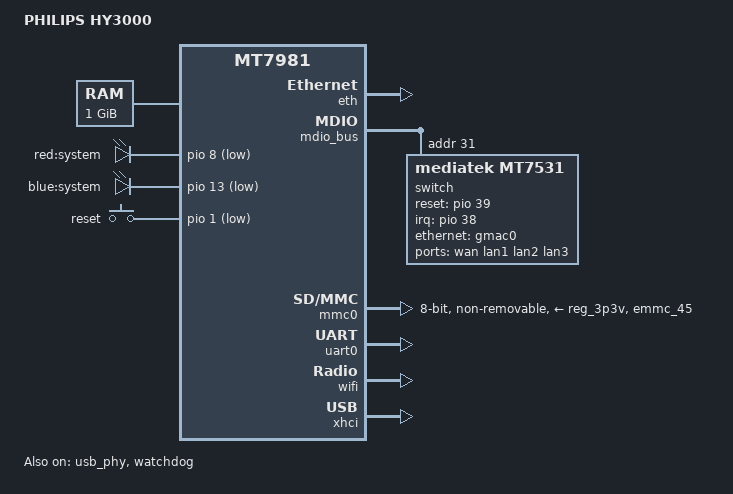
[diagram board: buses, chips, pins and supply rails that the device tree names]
// SPDX-License-Identifier: GPL-2.0-or-later OR MIT
/*
 * Copyright (C) 2023 Tianling Shen <cnsztl@immortalwrt.org>
 */

/dts-v1/;
#include <dt-bindings/gpio/gpio.h>
#include <dt-bindings/input/input.h>

#include "mt7981.dtsi"

/ {
	model = "PHILIPS HY3000";
	compatible = "philips,hy3000", "mediatek,mt7981";

	chosen {
		bootargs = "console=ttyS0,115200n1 loglevel=8 \
			    earlycon=uart8250,mmio32,0x11002000 \
			    root=PARTLABEL=rootfs rootwait rootfstype=squashfs,f2fs";
	};

	aliases {
		led-boot = &status_red_led;
		led-failsafe = &status_red_led;
		led-running = &status_blue_led;
		led-upgrade = &status_blue_led;
	};

	memory {
		reg = <0 0x40000000 0 0x40000000>;
	};

        leds {
                compatible = "gpio-leds";

		status_red_led: led@0 {
			label = "red:system";
			gpios = <&pio 8 GPIO_ACTIVE_LOW>;
		};

		status_blue_led: led@1 {
			label = "blue:system";
			gpios = <&pio 13 GPIO_ACTIVE_LOW>;
		};
	};

	gpio-keys {
		compatible = "gpio-keys";
		reset {
			label = "reset";
			linux,code = <KEY_RESTART>;
			gpios = <&pio 1 GPIO_ACTIVE_LOW>;
		};
	};
};

&eth {
	status = "okay";

	gmac0: mac@0 {
		compatible = "mediatek,eth-mac";
		reg = <0>;
		phy-mode = "2500base-x";

		fixed-link {
			speed = <2500>;
			full-duplex;
			pause;
		};
	};
	
	gmac1: mac@1 {
		compatible = "mediatek,eth-mac";
		reg = <1>;
		phy-mode = "2500base-x";

		fixed-link {
			speed = <2500>;
			full-duplex;
			pause;
		};
	};
};

&mdio_bus {
	switch: switch@1f {
		compatible = "mediatek,mt7531";
		reg = <31>;
		reset-gpios = <&pio 39 GPIO_ACTIVE_HIGH>;
		interrupt-controller;
		#interrupt-cells = <1>;
		interrupt-parent = <&pio>;
		interrupts = <38 IRQ_TYPE_LEVEL_HIGH>;
	};
};

&switch {
	ports {
		#address-cells = <1>;
		#size-cells = <0>;

		port@0 {
			reg = <0>;
			label = "wan";
		};

		port@1 {
			reg = <1>;
			label = "lan1";
		};

		port@2 {
			reg = <2>;
			label = "lan2";
		};
		
		port@3 {
			reg = <3>;
			label = "lan3";
		};

		port@6 {
			reg = <6>;
			ethernet = <&gmac0>;
			phy-mode = "2500base-x";

			fixed-link {
				speed = <2500>;
				full-duplex;
				pause;
			};
		};
	};
};

&mmc0 {
	bus-width = <8>;
	cap-mmc-highspeed;
	max-frequency = <52000000>;
	no-sd;
	no-sdio;
	non-removable;
	pinctrl-names = "default", "state_uhs";
	pinctrl-0 = <&mmc0_pins_default>;
	pinctrl-1 = <&mmc0_pins_uhs>;
	vmmc-supply = <&reg_3p3v>;
	non-removable;
	status = "okay";
};

&pio {
	mmc0_pins_default: mmc0-pins-default {
		mux {
			function = "flash";
			groups = "emmc_45";
		};
	};

	mmc0_pins_uhs: mmc0-pins-uhs {
		mux {
			function = "flash";
			groups = "emmc_45";
		};
	};
};

&uart0 {
	status = "okay";
};

&usb_phy {
	status = "okay";
};

&watchdog {
	status = "okay";
};

&wifi {
	status = "okay";
};

&xhci {
	status = "okay";
};
